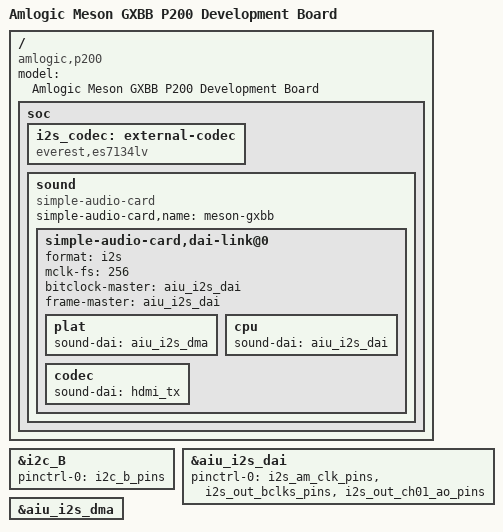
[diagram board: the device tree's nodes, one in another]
/*
 * Copyright (c) 2016 Andreas Färber
 * Copyright (c) 2016 BayLibre, Inc.
 * Author: Kevin Hilman <khilman@kernel.org>
 *
 * This file is dual-licensed: you can use it either under the terms
 * of the GPL or the X11 license, at your option. Note that this dual
 * licensing only applies to this file, and not this project as a
 * whole.
 *
 *  a) This library is free software; you can redistribute it and/or
 *     modify it under the terms of the GNU General Public License as
 *     published by the Free Software Foundation; either version 2 of the
 *     License, or (at your option) any later version.
 *
 *     This library is distributed in the hope that it will be useful,
 *     but WITHOUT ANY WARRANTY; without even the implied warranty of
 *     MERCHANTABILITY or FITNESS FOR A PARTICULAR PURPOSE.  See the
 *     GNU General Public License for more details.
 *
 * Or, alternatively,
 *
 *  b) Permission is hereby granted, free of charge, to any person
 *     obtaining a copy of this software and associated documentation
 *     files (the "Software"), to deal in the Software without
 *     restriction, including without limitation the rights to use,
 *     copy, modify, merge, publish, distribute, sublicense, and/or
 *     sell copies of the Software, and to permit persons to whom the
 *     Software is furnished to do so, subject to the following
 *     conditions:
 *
 *     The above copyright notice and this permission notice shall be
 *     included in all copies or substantial portions of the Software.
 *
 *     THE SOFTWARE IS PROVIDED "AS IS", WITHOUT WARRANTY OF ANY KIND,
 *     EXPRESS OR IMPLIED, INCLUDING BUT NOT LIMITED TO THE WARRANTIES
 *     OF MERCHANTABILITY, FITNESS FOR A PARTICULAR PURPOSE AND
 *     NONINFRINGEMENT. IN NO EVENT SHALL THE AUTHORS OR COPYRIGHT
 *     HOLDERS BE LIABLE FOR ANY CLAIM, DAMAGES OR OTHER LIABILITY,
 *     WHETHER IN AN ACTION OF CONTRACT, TORT OR OTHERWISE, ARISING
 *     FROM, OUT OF OR IN CONNECTION WITH THE SOFTWARE OR THE USE OR
 *     OTHER DEALINGS IN THE SOFTWARE.
 */

/dts-v1/;

#include "meson-gxbb-p20x.dtsi"

/ {
	compatible = "amlogic,p200", "amlogic,meson-gxbb";
	model = "Amlogic Meson GXBB P200 Development Board";

	soc {
		i2s_codec: external-codec {
			#sound-dai-cells = <0>;
			compatible = "everest,es7134lv";
			status = "okay";
		};

		sound {
			compatible = "simple-audio-card";
			simple-audio-card,name = "meson-gxbb";
			status = "okay";

			simple-audio-card,dai-link@0 {
				/* RCA Output */
				format = "i2s";
				mclk-fs = <256>;
				bitclock-master =  <&aiu_i2s_dai>;
				frame-master = <&aiu_i2s_dai>;
				plat {
					sound-dai = <&aiu_i2s_dma>;
				};

				cpu {
					sound-dai = <&aiu_i2s_dai>;
				};

				codec {
					//sound-dai = <&i2s_codec>;
					sound-dai = <&hdmi_tx>;
				};
			};
		};
	};
};

&i2c_B {
	status = "okay";
	pinctrl-0 = <&i2c_b_pins>;
	pinctrl-names = "default";
};

&aiu_i2s_dai {
	pinctrl-0 = <&i2s_am_clk_pins>, <&i2s_out_bclks_pins>,
		    <&i2s_out_ch01_ao_pins>;
	pinctrl-names = "default";
	status = "okay";
};

&aiu_i2s_dma {
	status = "okay";
};

